VERSION ""

NS_ :

BS_:

BU_: EMBEDDED VCU RES

BO_ 125 DV_Driver: 1 EMBEDDED
 SG_ Throttle : 0|8@1- (1,0) [-100|100] "%" VCU

BO_ 126 DV_EMBEDDED_Status: 1 EMBEDDED
 SG_ Embedded_status : 0|3@1+ (1,0) [1|5] "" VCU

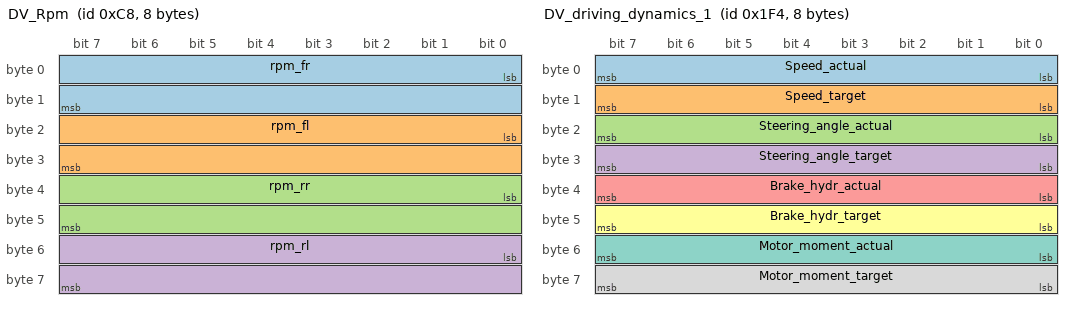
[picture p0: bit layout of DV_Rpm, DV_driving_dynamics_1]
BO_ 200 DV_Rpm: 8 VCU
 SG_ rpm_fr : 0|16@1+ (1,0) [0|18000] "rpm" EMBEDDED
 SG_ rpm_fl : 16|16@1+ (1,0) [0|18000] "rpm" EMBEDDED
 SG_ rpm_rr : 32|16@1+ (1,0) [0|18000] "rpm" EMBEDDED
 SG_ rpm_rl : 48|16@1+ (1,0) [0|18000] "rpm" EMBEDDED

BO_ 500 DV_driving_dynamics_1: 8 EMBEDDED
 SG_ Speed_actual : 0|8@1+ (1,0) [0|255] "km/h"  EMBEDDED
 SG_ Speed_target : 8|8@1+ (1,0) [0|255] "km/h"  EMBEDDED
 SG_ Steering_angle_actual : 16|8@1- (0.5,0) [-127|127] "°"  EMBEDDED
 SG_ Steering_angle_target : 24|8@1- (0.5,0) [-127|127] "°"  EMBEDDED
 SG_ Brake_hydr_actual : 32|8@1+ (1,0) [0|100] "%"  EMBEDDED
 SG_ Brake_hydr_target : 40|8@1+ (1,0) [0|100] "%"  EMBEDDED
 SG_ Motor_moment_actual : 48|8@1- (1,0) [-128|127] "%"  EMBEDDED
 SG_ Motor_moment_target : 56|8@1- (1,0) [-128|127] "%"  EMBEDDED

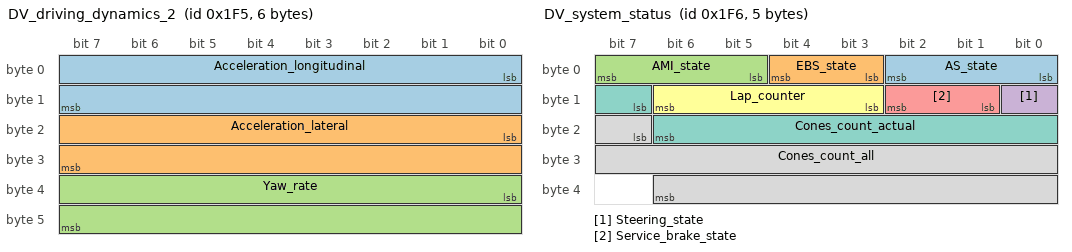
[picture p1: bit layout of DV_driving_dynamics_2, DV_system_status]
BO_ 501 DV_driving_dynamics_2: 6 EMBEDDED
 SG_ Acceleration_longitudinal : 0|16@1- (0.0005,0) [-16.384|16.384] "m/s²"  EMBEDDED
 SG_ Acceleration_lateral : 16|16@1- (0.0005,0) [-16.384|16.384] "m/s²"  EMBEDDED
 SG_ Yaw_rate : 32|16@1- (0.0078125,0) [-256|256] "°/s"  EMBEDDED

BO_ 502 DV_system_status: 5 EMBEDDED
 SG_ AS_state : 0|3@1+ (1,0) [0|7] ""  EMBEDDED
 SG_ EBS_state : 3|2@1+ (1,0) [0|3] ""  EMBEDDED
 SG_ AMI_state : 5|3@1+ (1,0) [0|7] ""  EMBEDDED
 SG_ Steering_state : 8|1@1+ (1,0) [0|1] "bool"  EMBEDDED
 SG_ Service_brake_state : 9|2@1+ (1,0) [0|3] ""  EMBEDDED
 SG_ Lap_counter : 11|4@1+ (1,0) [0|15] ""  EMBEDDED
 SG_ Cones_count_actual : 15|8@1+ (1,0) [0|255] ""  EMBEDDED
 SG_ Cones_count_all : 23|16@1+ (1,0) [0|65535] ""  EMBEDDED

BO_ 1809 DV_RES_On: 1 RES
 SG_ On : 0|8@1+ (1,0) [0|0] "" Vector__XXX

BO_ 0 DV_RES_OperationalMode: 2 VCU
 SG_ RequestedState : 0|8@1+ (1,0) [0|0] "" Vector__XXX
 SG_ Address : 8|8@1+ (1,0) [0|0] "" Vector__XXX

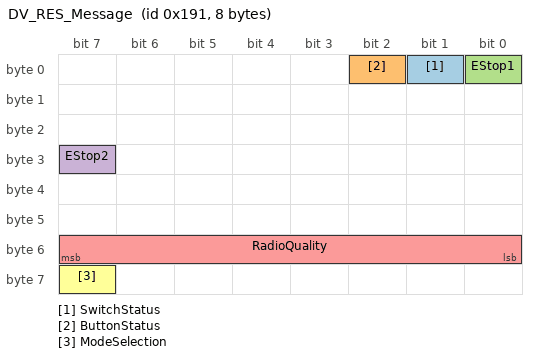
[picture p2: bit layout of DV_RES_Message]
BO_ 401 DV_RES_Message: 8 RES
 SG_ SwitchStatus : 1|1@1+ (1,0) [0|0] "" Vector__XXX
 SG_ ButtonStatus : 2|1@1+ (1,0) [0|0] "" Vector__XXX
 SG_ EStop1 : 0|1@1+ (1,0) [0|0] "" Vector__XXX
 SG_ EStop2 : 31|1@1+ (1,0) [0|0] "" Vector__XXX
 SG_ RadioQuality : 48|8@1+ (1,0) [0|100] "%" Vector__XXX
 SG_ ModeSelection : 63|1@1+ (1,0) [0|0] "" Vector__XXX

CM_ SG_ 502 AS_state "AS state off=1, ready=2, driving=3, emergency brake=4, finish=5.";
CM_ SG_ 502 EBS_state "EBS state unavailable=1, armed=2, activated=3.";
CM_ SG_ 502 AMI_state "AMI state acceleration=1, skidpad=2, trackdrive=3, braketest=4, inspection=5, autocross=6.";
CM_ SG_ 502 Service_brake_state "Disengaged=1, Engaged=2, Available=3.";
CM_ SG_ 1792 On "If byte == 0 then RES is ON";
CM_ SG_ 0 Address "If 0 then everyone (our case)";
VAL_ 126 Embedded_status 5 "finished" 4 "error" 3 "running" 2 "ready" 1 "off" ;
VAL_ 502 AS_state 5 "finish" 4 "emergency_brake" 3 "driving" 2 "ready" 1 "off" ;
VAL_ 502 EBS_state 3 "activated" 2 "armed" 1 "unavailable" ;
VAL_ 502 AMI_state 6 "autocross" 5 "inspection" 4 "braketest" 3 "trackdrive" 2 "skidpad" 1 "acceleration" ;
VAL_ 502 Service_brake_state 3 "available" 2 "engaged" 1 "disengaged" ;
VAL_ 1792 On 0 "ON" ;
VAL_ 0 RequestedState 1 "Operational" 128 "Check_ON" ;
VAL_ 0 Address 0 "All" ;
